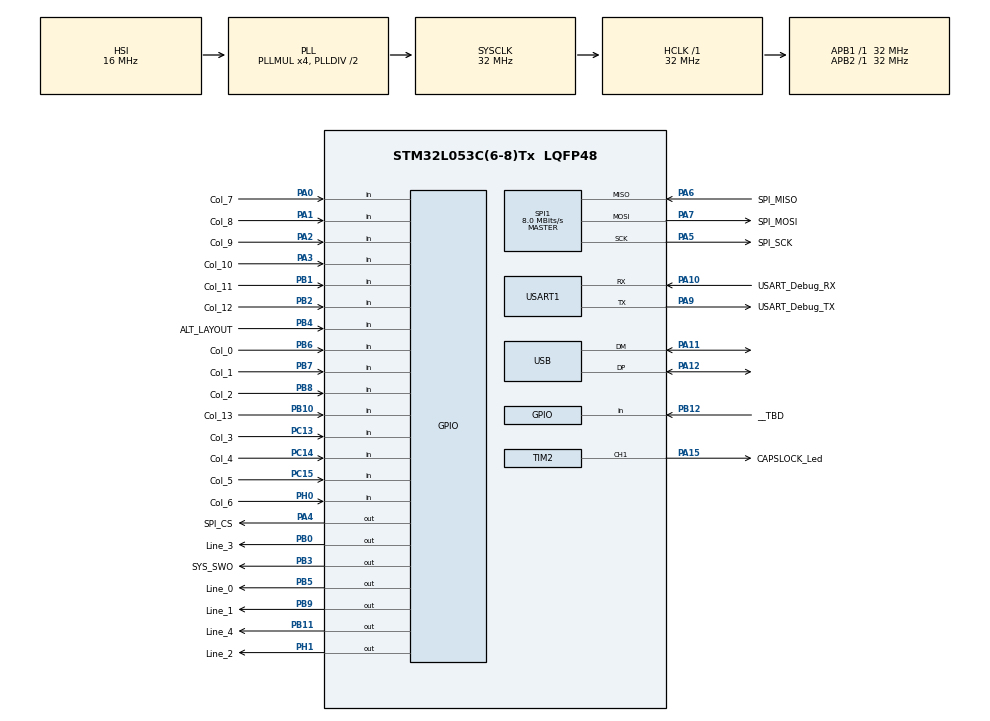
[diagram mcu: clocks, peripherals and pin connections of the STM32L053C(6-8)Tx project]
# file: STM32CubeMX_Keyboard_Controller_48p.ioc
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CRC.InputDataFormat=CRC_INPUTDATA_FORMAT_WORDS
Dma.Request0=SPI1_TX
Dma.SPI1_TX.0.Direction=DMA_MEMORY_TO_PERIPH
Dma.SPI1_TX.0.Instance=DMA1_Channel3
Dma.SPI1_TX.0.MemDataAlignment=DMA_MDATAALIGN_BYTE
Dma.SPI1_TX.0.MemInc=DMA_MINC_ENABLE
Dma.SPI1_TX.0.Mode=DMA_NORMAL
Dma.SPI1_TX.0.PeriphDataAlignment=DMA_PDATAALIGN_BYTE
Dma.SPI1_TX.0.PeriphInc=DMA_PINC_DISABLE
Dma.SPI1_TX.0.Priority=DMA_PRIORITY_MEDIUM
FREERTOS.HEAP_NUMBER=1
FREERTOS.Tasks01=USBTask,0,64,StartUSBTask,As weak;LedTask,-1,64,StartLedTask,As weak;ScanTask,1,64,StartScanTask,As weak;CommTask,-1,64,StartCommTask,As weak
FREERTOS.configENABLE_BACKWARD_COMPATIBILITY=0
FREERTOS.configMINIMAL_STACK_SIZE=64
FREERTOS.configQUEUE_REGISTRY_SIZE=0
FREERTOS.configTOTAL_HEAP_SIZE=3072
FREERTOS.configUSE_MUTEXES=0
FREERTOS.configUSE_TASK_NOTIFICATIONS=1
FREERTOS.configUSE_TRACE_FACILITY=0
Mcu.Family=STM32L0
Mcu.Name=STM32L053C(6-8)Tx
Mcu.Package=LQFP48
NVIC.DMA1_Channel2_3_IRQn=true\:3\:0\:false\:false\:true\:true
NVIC.TIM6_DAC_IRQn=true\:0\:0\:false\:false\:true\:false
NVIC.TimeBase=TIM6_DAC_IRQn
NVIC.TimeBaseIP=TIM6
NVIC.USB_IRQn=true\:3\:0\:false\:false\:true\:true
PA0.GPIO_Label=Col_7
PA0.GPIO_Mode=GPIO_MODE_INPUT
PA0.GPIO_PuPd=GPIO_PULLDOWN
PA0.Signal=GPIO_Input
PA1.GPIO_Label=Col_8
PA1.GPIO_Mode=GPIO_MODE_INPUT
PA1.GPIO_PuPd=GPIO_PULLDOWN
PA1.Signal=GPIO_Input
PA10.GPIO_Label=USART_Debug_RX
PA10.Mode=Asynchronous
PA10.Signal=USART1_RX
PA11.Mode=Device
PA11.Signal=USB_DM
PA12.Mode=Device
PA12.Signal=USB_DP
PA13.Mode=Serial_Wire
PA13.Signal=SYS_SWDIO
PA14.Mode=Serial_Wire
PA14.Signal=SYS_SWCLK
PA15.GPIO_Label=CAPSLOCK_Led
PA15.GPIO_ModeDefaultPP=GPIO_MODE_AF_OD
PA15.GPIO_Speed=GPIO_SPEED_FREQ_HIGH
PA15.Signal=S_TIM2_CH1
PA2.GPIO_Label=Col_9
PA2.GPIO_Mode=GPIO_MODE_INPUT
PA2.GPIO_PuPd=GPIO_PULLDOWN
PA2.Signal=GPIO_Input
PA3.GPIO_Label=Col_10
PA3.GPIO_Mode=GPIO_MODE_INPUT
PA3.GPIO_PuPd=GPIO_PULLDOWN
PA3.Signal=GPIO_Input
PA4.GPIO_Label=SPI_CS
PA4.GPIO_Speed=GPIO_SPEED_FREQ_HIGH
PA4.Signal=GPIO_Output
PA5.GPIO_Label=SPI_SCK
PA5.Mode=Full_Duplex_Master
PA5.Signal=SPI1_SCK
PA6.GPIO_Label=SPI_MISO
PA6.GPIO_PuPd=GPIO_NOPULL
PA6.Mode=Full_Duplex_Master
PA6.Signal=SPI1_MISO
PA7.GPIO_Label=SPI_MOSI
PA7.Mode=Full_Duplex_Master
PA7.Signal=SPI1_MOSI
PA9.GPIO_Label=USART_Debug_TX
PA9.Mode=Asynchronous
PA9.Signal=USART1_TX
PB0.GPIO_Label=Line_3
PB0.GPIO_Speed=GPIO_SPEED_FREQ_HIGH
PB0.Signal=GPIO_Output
PB1.GPIO_Label=Col_11
PB1.GPIO_Mode=GPIO_MODE_INPUT
PB1.GPIO_PuPd=GPIO_PULLDOWN
PB1.Signal=GPIO_Input
PB10.GPIO_Label=Col_13
PB10.GPIO_Mode=GPIO_MODE_INPUT
PB10.GPIO_PuPd=GPIO_PULLDOWN
PB10.Signal=GPIO_Input
PB11.GPIO_Label=Line_4
PB11.GPIO_Speed=GPIO_SPEED_FREQ_HIGH
PB11.Signal=GPIO_Output
PB12.GPIO_Label=__TBD
PB12.GPIO_PuPd=GPIO_PULLDOWN
PB12.Signal=GPIO_Input
PB2.GPIO_Label=Col_12
PB2.GPIO_Mode=GPIO_MODE_INPUT
PB2.GPIO_PuPd=GPIO_PULLDOWN
PB2.Signal=GPIO_Input
PB3.GPIO_Label=SYS_SWO
PB3.GPIO_Speed=GPIO_SPEED_FREQ_HIGH
PB3.Signal=GPIO_Output
PB4.GPIO_Label=ALT_LAYOUT
PB4.GPIO_PuPd=GPIO_PULLDOWN
PB4.Signal=GPIO_Input
PB5.GPIO_Label=Line_0
PB5.GPIO_Speed=GPIO_SPEED_FREQ_HIGH
PB5.Signal=GPIO_Output
PB6.GPIO_Label=Col_0
PB6.GPIO_Mode=GPIO_MODE_INPUT
PB6.GPIO_PuPd=GPIO_PULLDOWN
PB6.Signal=GPIO_Input
PB7.GPIO_Label=Col_1
PB7.GPIO_Mode=GPIO_MODE_INPUT
PB7.GPIO_PuPd=GPIO_PULLDOWN
PB7.Signal=GPIO_Input
PB8.GPIO_Label=Col_2
PB8.GPIO_Mode=GPIO_MODE_INPUT
PB8.GPIO_PuPd=GPIO_PULLDOWN
PB8.Signal=GPIO_Input
PB9.GPIO_Label=Line_1
PB9.GPIO_Speed=GPIO_SPEED_FREQ_HIGH
PB9.Signal=GPIO_Output
PC13.GPIO_Label=Col_3
PC13.GPIO_Mode=GPIO_MODE_INPUT
PC13.GPIO_PuPd=GPIO_PULLDOWN
PC13.Signal=GPIO_Input
PC14-OSC32_IN.GPIO_Label=Col_4
PC14-OSC32_IN.GPIO_Mode=GPIO_MODE_INPUT
PC14-OSC32_IN.GPIO_PuPd=GPIO_PULLDOWN
PC14-OSC32_IN.Signal=GPIO_Input
PC15-OSC32_OUT.GPIO_Label=Col_5
PC15-OSC32_OUT.GPIO_Mode=GPIO_MODE_INPUT
PC15-OSC32_OUT.GPIO_PuPd=GPIO_PULLDOWN
PC15-OSC32_OUT.Signal=GPIO_Input
PH0-OSC_IN.GPIO_Label=Col_6
PH0-OSC_IN.GPIO_Mode=GPIO_MODE_INPUT
PH0-OSC_IN.GPIO_PuPd=GPIO_PULLDOWN
PH0-OSC_IN.Signal=GPIO_Input
PH1-OSC_OUT.GPIO_Label=Line_2
PH1-OSC_OUT.GPIO_Speed=GPIO_SPEED_FREQ_HIGH
PH1-OSC_OUT.Signal=GPIO_Output
ProjectManager.HeapSize=0x0
ProjectManager.StackSize=0x200
ProjectManager.TargetToolchain=TrueSTUDIO
RCC.AHBFreq_Value=32000000
RCC.APB1Freq_Value=32000000
RCC.APB1TimFreq_Value=32000000
RCC.APB2Freq_Value=32000000
RCC.APB2TimFreq_Value=32000000
RCC.HCLKFreq_Value=32000000
RCC.HSE_VALUE=8000000
RCC.HSI16_VALUE=16000000
RCC.HSI48MClockSelection=RCC_USBCLKSOURCE_HSI48
RCC.HSI48_VALUE=48000000
RCC.HSI_VALUE=16000000
RCC.LSE_VALUE=32768
RCC.MSI_VALUE=2097000
RCC.PLLMUL=RCC_PLLMUL_4
RCC.SYSCLKFreq_VALUE=32000000
RCC.SYSCLKSource=RCC_SYSCLKSOURCE_PLLCLK
RCC.VCOOutputFreq_Value=64000000
SH.S_TIM2_CH1.0=TIM2_CH1,PWM Generation1 CH1
SPI1.BaudRatePrescaler=SPI_BAUDRATEPRESCALER_4
SPI1.CRCCalculation=SPI_CRCCALCULATION_DISABLE
SPI1.CalculateBaudRate=8.0 MBits/s
SPI1.Mode=SPI_MODE_MASTER
SPI1.NSSPMode=SPI_NSS_PULSE_DISABLE
TIM2.OCFastMode_PWM-PWM\ Generation1\ CH1=TIM_OCFAST_ENABLE
TIM2.OCPolarity_1=TIM_OCPOLARITY_LOW
TIM2.Period=1000
TIM2.Prescaler=32
TIM2.Pulse-PWM\ Generation1\ CH1=0
USART1.WordLength=UART_WORDLENGTH_8B
USB_DEVICE.MANUFACTURER_STRING=/u/Ced67
USB_DEVICE.PRODUCT_STRING_HID_FS=TCKB
USB_DEVICE.USBD_HandleTypeDef=hUsbDeviceFS
USB_DEVICE.VirtualMode=Hid
USB_DEVICE.VirtualModeFS=Hid_FS
VP_CRC_VS_CRC.Mode=CRC_Activate
VP_FREERTOS_VS_ENABLE.Mode=Enabled
VP_SYS_VS_tim6.Mode=TIM6
VP_TIM2_VS_ClockSourceINT.Mode=Internal
VP_USB_DEVICE_VS_USB_DEVICE_HID_FS.Mode=HID_FS
board=STM32CubeMX_Keyboard_Controller_48p

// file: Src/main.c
/**
  ******************************************************************************
  * File Name          : main.c
  * Description        : Main program body
  ******************************************************************************
  *
  * Copyright (c) 2017 STMicroelectronics International N.V.
  * All rights reserved.
  *
  * Redistribution and use in source and binary forms, with or without
  * modification, are permitted, provided that the following conditions are met:
  *
  * 1. Redistribution of source code must retain the above copyright notice,
  *    this list of conditions and the following disclaimer.
  * 2. Redistributions in binary form must reproduce the above copyright notice,
  *    this list of conditions and the following disclaimer in the documentation
  *    and/or other materials provided with the distribution.
  * 3. Neither the name of STMicroelectronics nor the names of other
  *    contributors to this software may be used to endorse or promote products
  *    derived from this software without specific written permission.
  * 4. This software, including modifications and/or derivative works of this
  *    software, must execute solely and exclusively on microcontroller or
  *    microprocessor devices manufactured by or for STMicroelectronics.
  * 5. Redistribution and use of this software other than as permitted under
  *    this license is void and will automatically terminate your rights under
  *    this license.
  *
  * THIS SOFTWARE IS PROVIDED BY STMICROELECTRONICS AND CONTRIBUTORS "AS IS"
  * AND ANY EXPRESS, IMPLIED OR STATUTORY WARRANTIES, INCLUDING, BUT NOT
  * LIMITED TO, THE IMPLIED WARRANTIES OF MERCHANTABILITY, FITNESS FOR A
  * PARTICULAR PURPOSE AND NON-INFRINGEMENT OF THIRD PARTY INTELLECTUAL PROPERTY
  * RIGHTS ARE DISCLAIMED TO THE FULLEST EXTENT PERMITTED BY LAW. IN NO EVENT
  * SHALL STMICROELECTRONICS OR CONTRIBUTORS BE LIABLE FOR ANY DIRECT, INDIRECT,
  * INCIDENTAL, SPECIAL, EXEMPLARY, OR CONSEQUENTIAL DAMAGES (INCLUDING, BUT NOT
  * LIMITED TO, PROCUREMENT OF SUBSTITUTE GOODS OR SERVICES; LOSS OF USE, DATA,
  * OR PROFITS; OR BUSINESS INTERRUPTION) HOWEVER CAUSED AND ON ANY THEORY OF
  * LIABILITY, WHETHER IN CONTRACT, STRICT LIABILITY, OR TORT (INCLUDING
  * NEGLIGENCE OR OTHERWISE) ARISING IN ANY WAY OUT OF THE USE OF THIS SOFTWARE,
  * EVEN IF ADVISED OF THE POSSIBILITY OF SUCH DAMAGE.
  *
  ******************************************************************************
  */
#include "main.h"
#include "stm32l0xx_hal.h"
#include "cmsis_os.h"
#include "usb_device.h"

/* USER CODE BEGIN Includes */
#include "Utils.h"
#include "HID_Report.h"
#include "Mailboxes.h"
/* USER CODE END Includes */

CRC_HandleTypeDef hcrc;

SPI_HandleTypeDef hspi1;
DMA_HandleTypeDef hdma_spi1_tx;

TIM_HandleTypeDef htim2;

UART_HandleTypeDef huart1;

osThreadId USBTaskHandle;
osThreadId LedTaskHandle;
osThreadId ScanTaskHandle;
osThreadId CommTaskHandle;

/* USER CODE BEGIN PV */
/* Private variables ---------------------------------------------------------*/

/* USER CODE END PV */

void SystemClock_Config(void);
void Error_Handler(void);
static void MX_GPIO_Init(void);
static void MX_DMA_Init(void);
static void MX_SPI1_Init(void);
static void MX_TIM2_Init(void);
static void MX_USART1_UART_Init(void);
static void MX_CRC_Init(void);
void StartUSBTask(void const * argument);
void StartLedTask(void const * argument);
void StartScanTask(void const * argument);
void StartCommTask(void const * argument);

void HAL_TIM_MspPostInit(TIM_HandleTypeDef *htim);

/* USER CODE BEGIN PFP */
/* Private function prototypes -----------------------------------------------*/

/* USER CODE END PFP */

int main(void)
{

  /* USER CODE BEGIN 1 */
  Utils_Init();
  /* USER CODE END 1 */

  /* MCU Configuration----------------------------------------------------------*/

  /* Reset of all peripherals, Initializes the Flash interface and the Systick. */
  HAL_Init();

  /* Configure the system clock */
  SystemClock_Config();

  /* Initialize all configured peripherals */
  MX_GPIO_Init();
  MX_DMA_Init();
  MX_SPI1_Init();
  MX_TIM2_Init();
  MX_USART1_UART_Init();
  MX_CRC_Init();

  /* USER CODE BEGIN 2 */
  //Create Mailboxes
  TCKB_Init_KRO6_Mailbox();
  TCKB_Init_SERIAL_Mailbox();
  /* USER CODE END 2 */

  /* Create the thread(s) */
  /* definition and creation of USBTask */
  osThreadDef(USBTask, StartUSBTask, osPriorityNormal, 0, 64);
  USBTaskHandle = osThreadCreate(osThread(USBTask), NULL);

  /* definition and creation of LedTask */
  osThreadDef(LedTask, StartLedTask, osPriorityBelowNormal, 0, 64);
  LedTaskHandle = osThreadCreate(osThread(LedTask), NULL);

  /* definition and creation of ScanTask */
  osThreadDef(ScanTask, StartScanTask, osPriorityAboveNormal, 0, 64);
  ScanTaskHandle = osThreadCreate(osThread(ScanTask), NULL);

  /* definition and creation of CommTask */
  osThreadDef(CommTask, StartCommTask, osPriorityBelowNormal, 0, 64);
  CommTaskHandle = osThreadCreate(osThread(CommTask), NULL);

  /* Start scheduler */
  osKernelStart();

  /* We should never get here as control is now taken by the scheduler */

  /* Infinite loop */
  while (1)
  {

  }

}

/** System Clock Configuration
*/
void SystemClock_Config(void)
{

  RCC_OscInitTypeDef RCC_OscInitStruct;
  RCC_ClkInitTypeDef RCC_ClkInitStruct;
  RCC_PeriphCLKInitTypeDef PeriphClkInit;

    /**Configure the main internal regulator output voltage
    */
  __HAL_PWR_VOLTAGESCALING_CONFIG(PWR_REGULATOR_VOLTAGE_SCALE1);

    /**Initializes the CPU, AHB and APB busses clocks
    */
  RCC_OscInitStruct.OscillatorType = RCC_OSCILLATORTYPE_HSI|RCC_OSCILLATORTYPE_HSI48;
  RCC_OscInitStruct.HSIState = RCC_HSI_ON;
  RCC_OscInitStruct.HSICalibrationValue = 16;
  RCC_OscInitStruct.HSI48State = RCC_HSI48_ON;
  RCC_OscInitStruct.PLL.PLLState = RCC_PLL_ON;
  RCC_OscInitStruct.PLL.PLLSource = RCC_PLLSOURCE_HSI;
  RCC_OscInitStruct.PLL.PLLMUL = RCC_PLLMUL_4;
  RCC_OscInitStruct.PLL.PLLDIV = RCC_PLLDIV_2;
  if (HAL_RCC_OscConfig(&RCC_OscInitStruct) != HAL_OK)
  {
    Error_Handler();
  }

    /**Initializes the CPU, AHB and APB busses clocks
    */
  RCC_ClkInitStruct.ClockType = RCC_CLOCKTYPE_HCLK|RCC_CLOCKTYPE_SYSCLK
                              |RCC_CLOCKTYPE_PCLK1|RCC_CLOCKTYPE_PCLK2;
  RCC_ClkInitStruct.SYSCLKSource = RCC_SYSCLKSOURCE_PLLCLK;
  RCC_ClkInitStruct.AHBCLKDivider = RCC_SYSCLK_DIV1;
  RCC_ClkInitStruct.APB1CLKDivider = RCC_HCLK_DIV1;
  RCC_ClkInitStruct.APB2CLKDivider = RCC_HCLK_DIV1;

  if (HAL_RCC_ClockConfig(&RCC_ClkInitStruct, FLASH_LATENCY_1) != HAL_OK)
  {
    Error_Handler();
  }

  PeriphClkInit.PeriphClockSelection = RCC_PERIPHCLK_USART1|RCC_PERIPHCLK_USB;
  PeriphClkInit.Usart1ClockSelection = RCC_USART1CLKSOURCE_PCLK2;
  PeriphClkInit.UsbClockSelection = RCC_USBCLKSOURCE_HSI48;
  if (HAL_RCCEx_PeriphCLKConfig(&PeriphClkInit) != HAL_OK)
  {
    Error_Handler();
  }

    /**Configure the Systick interrupt time
    */
  HAL_SYSTICK_Config(HAL_RCC_GetHCLKFreq()/1000);

    /**Configure the Systick
    */
  HAL_SYSTICK_CLKSourceConfig(SYSTICK_CLKSOURCE_HCLK);

  /* SysTick_IRQn interrupt configuration */
  HAL_NVIC_SetPriority(SysTick_IRQn, 3, 0);
}

/* CRC init function */
static void MX_CRC_Init(void)
{

  hcrc.Instance = CRC;
  hcrc.Init.DefaultPolynomialUse = DEFAULT_POLYNOMIAL_ENABLE;
  hcrc.Init.DefaultInitValueUse = DEFAULT_INIT_VALUE_ENABLE;
  hcrc.Init.InputDataInversionMode = CRC_INPUTDATA_INVERSION_NONE;
  hcrc.Init.OutputDataInversionMode = CRC_OUTPUTDATA_INVERSION_DISABLE;
  hcrc.InputDataFormat = CRC_INPUTDATA_FORMAT_WORDS;
  if (HAL_CRC_Init(&hcrc) != HAL_OK)
  {
    Error_Handler();
  }

}

/* SPI1 init function */
static void MX_SPI1_Init(void)
{

  hspi1.Instance = SPI1;
  hspi1.Init.Mode = SPI_MODE_MASTER;
  hspi1.Init.Direction = SPI_DIRECTION_2LINES;
  hspi1.Init.DataSize = SPI_DATASIZE_8BIT;
  hspi1.Init.CLKPolarity = SPI_POLARITY_LOW;
  hspi1.Init.CLKPhase = SPI_PHASE_1EDGE;
  hspi1.Init.NSS = SPI_NSS_SOFT;
  hspi1.Init.BaudRatePrescaler = SPI_BAUDRATEPRESCALER_4;
  hspi1.Init.FirstBit = SPI_FIRSTBIT_MSB;
  hspi1.Init.TIMode = SPI_TIMODE_DISABLE;
  hspi1.Init.CRCCalculation = SPI_CRCCALCULATION_DISABLE;
  hspi1.Init.CRCPolynomial = 7;
  if (HAL_SPI_Init(&hspi1) != HAL_OK)
  {
    Error_Handler();
  }

}

/* TIM2 init function */
static void MX_TIM2_Init(void)
{

  TIM_ClockConfigTypeDef sClockSourceConfig;
  TIM_MasterConfigTypeDef sMasterConfig;
  TIM_OC_InitTypeDef sConfigOC;

  htim2.Instance = TIM2;
  htim2.Init.Prescaler = 32;
  htim2.Init.CounterMode = TIM_COUNTERMODE_UP;
  htim2.Init.Period = 1000;
  htim2.Init.ClockDivision = TIM_CLOCKDIVISION_DIV1;
  if (HAL_TIM_Base_Init(&htim2) != HAL_OK)
  {
    Error_Handler();
  }

  sClockSourceConfig.ClockSource = TIM_CLOCKSOURCE_INTERNAL;
  if (HAL_TIM_ConfigClockSource(&htim2, &sClockSourceConfig) != HAL_OK)
  {
    Error_Handler();
  }

  if (HAL_TIM_PWM_Init(&htim2) != HAL_OK)
  {
    Error_Handler();
  }

  sMasterConfig.MasterOutputTrigger = TIM_TRGO_RESET;
  sMasterConfig.MasterSlaveMode = TIM_MASTERSLAVEMODE_DISABLE;
  if (HAL_TIMEx_MasterConfigSynchronization(&htim2, &sMasterConfig) != HAL_OK)
  {
    Error_Handler();
  }

  sConfigOC.OCMode = TIM_OCMODE_PWM1;
  sConfigOC.Pulse = 0;
  sConfigOC.OCPolarity = TIM_OCPOLARITY_LOW;
  sConfigOC.OCFastMode = TIM_OCFAST_ENABLE;
  if (HAL_TIM_PWM_ConfigChannel(&htim2, &sConfigOC, TIM_CHANNEL_1) != HAL_OK)
  {
    Error_Handler();
  }

  HAL_TIM_MspPostInit(&htim2);

}

/* USART1 init function */
static void MX_USART1_UART_Init(void)
{

  huart1.Instance = USART1;
  huart1.Init.BaudRate = 115200;
  huart1.Init.WordLength = UART_WORDLENGTH_8B;
  huart1.Init.StopBits = UART_STOPBITS_1;
  huart1.Init.Parity = UART_PARITY_NONE;
  huart1.Init.Mode = UART_MODE_TX_RX;
  huart1.Init.HwFlowCtl = UART_HWCONTROL_NONE;
  huart1.Init.OverSampling = UART_OVERSAMPLING_16;
  huart1.Init.OneBitSampling = UART_ONE_BIT_SAMPLE_DISABLE;
  huart1.AdvancedInit.AdvFeatureInit = UART_ADVFEATURE_NO_INIT;
  if (HAL_UART_Init(&huart1) != HAL_OK)
  {
    Error_Handler();
  }

}

static void MX_DMA_Init(void)
{
  /* DMA controller clock enable */
  __HAL_RCC_DMA1_CLK_ENABLE();

  /* DMA interrupt init */
  /* DMA1_Channel2_3_IRQn interrupt configuration */
  HAL_NVIC_SetPriority(DMA1_Channel2_3_IRQn, 3, 0);
  HAL_NVIC_EnableIRQ(DMA1_Channel2_3_IRQn);

}

/** Configure pins as
        * Analog
        * Input
        * Output
        * EVENT_OUT
        * EXTI
*/
static void MX_GPIO_Init(void)
{

  GPIO_InitTypeDef GPIO_InitStruct;

  /* GPIO Ports Clock Enable */
  __HAL_RCC_GPIOC_CLK_ENABLE();
  __HAL_RCC_GPIOH_CLK_ENABLE();
  __HAL_RCC_GPIOA_CLK_ENABLE();
  __HAL_RCC_GPIOB_CLK_ENABLE();

  /*Configure GPIO pins : Col_3_Pin Col_4_Pin Col_5_Pin */
  GPIO_InitStruct.Pin = Col_3_Pin|Col_4_Pin|Col_5_Pin;
  GPIO_InitStruct.Mode = GPIO_MODE_INPUT;
  GPIO_InitStruct.Pull = GPIO_PULLDOWN;
  HAL_GPIO_Init(GPIOC, &GPIO_InitStruct);

  /*Configure GPIO pin : Col_6_Pin */
  GPIO_InitStruct.Pin = Col_6_Pin;
  GPIO_InitStruct.Mode = GPIO_MODE_INPUT;
  GPIO_InitStruct.Pull = GPIO_PULLDOWN;
  HAL_GPIO_Init(Col_6_GPIO_Port, &GPIO_InitStruct);

  /*Configure GPIO pin : Line_2_Pin */
  GPIO_InitStruct.Pin = Line_2_Pin;
  GPIO_InitStruct.Mode = GPIO_MODE_OUTPUT_PP;
  GPIO_InitStruct.Pull = GPIO_NOPULL;
  GPIO_InitStruct.Speed = GPIO_SPEED_FREQ_HIGH;
  HAL_GPIO_Init(Line_2_GPIO_Port, &GPIO_InitStruct);

  /*Configure GPIO pins : Col_7_Pin Col_8_Pin Col_9_Pin Col_10_Pin */
  GPIO_InitStruct.Pin = Col_7_Pin|Col_8_Pin|Col_9_Pin|Col_10_Pin;
  GPIO_InitStruct.Mode = GPIO_MODE_INPUT;
  GPIO_InitStruct.Pull = GPIO_PULLDOWN;
  HAL_GPIO_Init(GPIOA, &GPIO_InitStruct);

  /*Configure GPIO pin : SPI_CS_Pin */
  GPIO_InitStruct.Pin = SPI_CS_Pin;
  GPIO_InitStruct.Mode = GPIO_MODE_OUTPUT_PP;
  GPIO_InitStruct.Pull = GPIO_NOPULL;
  GPIO_InitStruct.Speed = GPIO_SPEED_FREQ_HIGH;
  HAL_GPIO_Init(SPI_CS_GPIO_Port, &GPIO_InitStruct);

  /*Configure GPIO pins : Line_3_Pin Line_4_Pin SYS_SWO_Pin Line_0_Pin
                           Line_1_Pin */
  GPIO_InitStruct.Pin = Line_3_Pin|Line_4_Pin|SYS_SWO_Pin|Line_0_Pin
                          |Line_1_Pin;
  GPIO_InitStruct.Mode = GPIO_MODE_OUTPUT_PP;
  GPIO_InitStruct.Pull = GPIO_NOPULL;
  GPIO_InitStruct.Speed = GPIO_SPEED_FREQ_HIGH;
  HAL_GPIO_Init(GPIOB, &GPIO_InitStruct);

  /*Configure GPIO pins : Col_11_Pin Col_12_Pin Col_13_Pin __TBD_Pin
                           ALT_LAYOUT_Pin Col_0_Pin Col_1_Pin Col_2_Pin */
  GPIO_InitStruct.Pin = Col_11_Pin|Col_12_Pin|Col_13_Pin|__TBD_Pin
                          |ALT_LAYOUT_Pin|Col_0_Pin|Col_1_Pin|Col_2_Pin;
  GPIO_InitStruct.Mode = GPIO_MODE_INPUT;
  GPIO_InitStruct.Pull = GPIO_PULLDOWN;
  HAL_GPIO_Init(GPIOB, &GPIO_InitStruct);

  /*Configure GPIO pin Output Level */
  HAL_GPIO_WritePin(Line_2_GPIO_Port, Line_2_Pin, GPIO_PIN_RESET);

  /*Configure GPIO pin Output Level */
  HAL_GPIO_WritePin(SPI_CS_GPIO_Port, SPI_CS_Pin, GPIO_PIN_RESET);

  /*Configure GPIO pin Output Level */
  HAL_GPIO_WritePin(GPIOB, Line_3_Pin|Line_4_Pin|SYS_SWO_Pin|Line_0_Pin
                          |Line_1_Pin, GPIO_PIN_RESET);

}

/* StartUSBTask function */
__weak void StartUSBTask(void const * argument)
{
  /* init code for USB_DEVICE */
  MX_USB_DEVICE_Init();

  for(;;)
  {
    osDelay(1);
  }
}

/* StartLedTask function */
__weak void StartLedTask(void const * argument)
{
  for(;;)
  {
    osDelay(1);
  }
}

/* StartScanTask function */
__weak void StartScanTask(void const * argument)
{
  for(;;)
  {
    osDelay(1);
  }
}

/* StartCommTask function */
__weak void StartCommTask(void const * argument)
{
  for(;;)
  {
    osDelay(1);
  }
}

void HAL_TIM_PeriodElapsedCallback(TIM_HandleTypeDef *htim)
{
  if (htim->Instance == TIM6) {
    HAL_IncTick();
  }
}

void Error_Handler(void)
{
  while(1)
  {
  }
}

/************************ (C) COPYRIGHT STMicroelectronics *****END OF FILE****/
